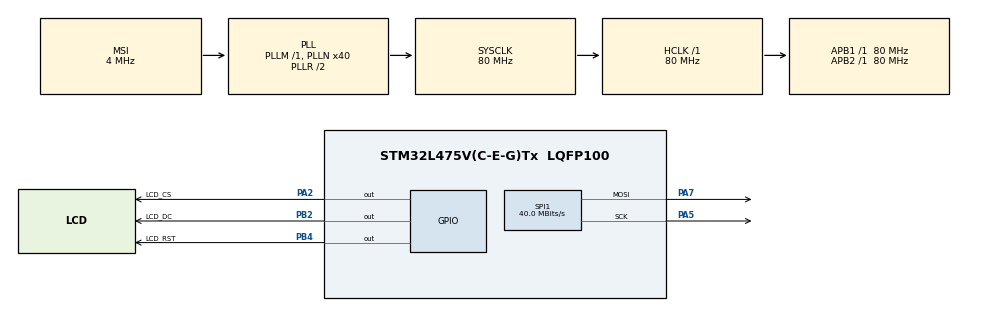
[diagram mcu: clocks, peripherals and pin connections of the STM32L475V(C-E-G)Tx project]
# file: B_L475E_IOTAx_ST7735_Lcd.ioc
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Mcu.Family=STM32L4
Mcu.Name=STM32L475V(C-E-G)Tx
Mcu.Package=LQFP100
NVIC.PriorityGroup=NVIC_PRIORITYGROUP_4
PA13\ (JTMS-SWDIO).Mode=Trace_Asynchronous_SW
PA13\ (JTMS-SWDIO).Signal=SYS_JTMS-SWDIO
PA14\ (JTCK-SWCLK).Mode=Trace_Asynchronous_SW
PA14\ (JTCK-SWCLK).Signal=SYS_JTCK-SWCLK
PA2.GPIO_Label=LCD_CS
PA2.Signal=GPIO_Output
PA5.Mode=TX_Only_Simplex_Unidirect_Master
PA5.Signal=SPI1_SCK
PA7.Mode=TX_Only_Simplex_Unidirect_Master
PA7.Signal=SPI1_MOSI
PB2.GPIO_Label=LCD_DC
PB2.Signal=GPIO_Output
PB3\ (JTDO-TRACESWO).Mode=Trace_Asynchronous_SW
PB3\ (JTDO-TRACESWO).Signal=SYS_JTDO-SWO
PB4\ (NJTRST).GPIO_Label=LCD_RST
PB4\ (NJTRST).Signal=GPIO_Output
ProjectManager.HeapSize=0x200
ProjectManager.StackSize=0x400
ProjectManager.TargetToolchain=STM32CubeIDE
RCC.ADCFreq_Value=48000000
RCC.AHBFreq_Value=80000000
RCC.APB1Freq_Value=80000000
RCC.APB1TimFreq_Value=80000000
RCC.APB2Freq_Value=80000000
RCC.APB2TimFreq_Value=80000000
RCC.CortexFreq_Value=80000000
RCC.HCLKFreq_Value=80000000
RCC.HSE_VALUE=8000000
RCC.HSI_VALUE=16000000
RCC.LSE_VALUE=32768
RCC.MSI_VALUE=4000000
RCC.PLLN=40
RCC.PLLSAI1N=24
RCC.SYSCLKFreq_VALUE=80000000
RCC.SYSCLKSource=RCC_SYSCLKSOURCE_PLLCLK
RCC.USBFreq_Value=48000000
RCC.VCOOutputFreq_Value=160000000
SPI1.BaudRatePrescaler=SPI_BAUDRATEPRESCALER_2
SPI1.CalculateBaudRate=40.0 MBits/s
SPI1.DataSize=SPI_DATASIZE_8BIT
SPI1.Direction=SPI_DIRECTION_2LINES
SPI1.Mode=SPI_MODE_MASTER
SPI1.NSSPMode=SPI_NSS_PULSE_DISABLE
SPI1.VirtualType=VM_MASTER
board=B-L475E-IOT01A1

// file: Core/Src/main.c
/* USER CODE BEGIN Header */
/**
  ******************************************************************************
  * @file           : main.c
  * @brief          : Main program body
  ******************************************************************************
  * @attention
  *
  * <h2><center>&copy; Copyright (c) 2020 STMicroelectronics.
  * All rights reserved.</center></h2>
  *
  * This software component is licensed by ST under BSD 3-Clause license,
  * the "License"; You may not use this file except in compliance with the
  * License. You may obtain a copy of the License at:
  *                        opensource.org/licenses/BSD-3-Clause
  *
  ******************************************************************************
  */
/* USER CODE END Header */

#include "main.h"

/* USER CODE BEGIN Includes */
#include <string.h>
#include <stdio.h>
#include "st7735.h"

/* USER CODE END Includes */

SPI_HandleTypeDef hspi1;

/* USER CODE BEGIN PV */
uint8_t val;
char str[4];

/* USER CODE END PV */

void SystemClock_Config(void);
static void MX_GPIO_Init(void);
static void MX_SPI1_Init(void);

int main(void)
{

  /* MCU Configuration--------------------------------------------------------*/

  /* Reset of all peripherals, Initializes the Flash interface and the Systick. */
  HAL_Init();

  /* Configure the system clock */
  SystemClock_Config();

  /* Initialize all configured peripherals */
  MX_GPIO_Init();
  MX_SPI1_Init();
  /* USER CODE BEGIN 2 */

  /**> Initialize 1.8inch LCD */
  LcdInit();

  /**> Configure Screen and Rotation */
  fillScreen(ST7735_GREY);
  setRotation(1);

  /* USER CODE END 2 */

  /* Infinite loop */
  /* USER CODE BEGIN WHILE */
  while (1)
  {
 		val++;
  	sprintf(str, "%3d", val);
  	drawString(str, 0, 0, ST7735_BLACK, ST7735_GREY, 3);
  	HAL_Delay(250);
  	/* USER CODE END WHILE */

  }
}

void SystemClock_Config(void)
{
  RCC_OscInitTypeDef RCC_OscInitStruct = {0};
  RCC_ClkInitTypeDef RCC_ClkInitStruct = {0};

  /** Initializes the CPU, AHB and APB busses clocks
  */
  RCC_OscInitStruct.OscillatorType = RCC_OSCILLATORTYPE_MSI;
  RCC_OscInitStruct.MSIState = RCC_MSI_ON;
  RCC_OscInitStruct.MSICalibrationValue = 0;
  RCC_OscInitStruct.MSIClockRange = RCC_MSIRANGE_6;
  RCC_OscInitStruct.PLL.PLLState = RCC_PLL_ON;
  RCC_OscInitStruct.PLL.PLLSource = RCC_PLLSOURCE_MSI;
  RCC_OscInitStruct.PLL.PLLM = 1;
  RCC_OscInitStruct.PLL.PLLN = 40;
  RCC_OscInitStruct.PLL.PLLP = RCC_PLLP_DIV7;
  RCC_OscInitStruct.PLL.PLLQ = RCC_PLLQ_DIV2;
  RCC_OscInitStruct.PLL.PLLR = RCC_PLLR_DIV2;
  if (HAL_RCC_OscConfig(&RCC_OscInitStruct) != HAL_OK)
  {
    Error_Handler();
  }
  /** Initializes the CPU, AHB and APB busses clocks
  */
  RCC_ClkInitStruct.ClockType = RCC_CLOCKTYPE_HCLK|RCC_CLOCKTYPE_SYSCLK
                              |RCC_CLOCKTYPE_PCLK1|RCC_CLOCKTYPE_PCLK2;
  RCC_ClkInitStruct.SYSCLKSource = RCC_SYSCLKSOURCE_PLLCLK;
  RCC_ClkInitStruct.AHBCLKDivider = RCC_SYSCLK_DIV1;
  RCC_ClkInitStruct.APB1CLKDivider = RCC_HCLK_DIV1;
  RCC_ClkInitStruct.APB2CLKDivider = RCC_HCLK_DIV1;

  if (HAL_RCC_ClockConfig(&RCC_ClkInitStruct, FLASH_LATENCY_4) != HAL_OK)
  {
    Error_Handler();
  }
  /** Configure the main internal regulator output voltage
  */
  if (HAL_PWREx_ControlVoltageScaling(PWR_REGULATOR_VOLTAGE_SCALE1) != HAL_OK)
  {
    Error_Handler();
  }
}

static void MX_SPI1_Init(void)
{

  /* SPI1 parameter configuration*/
  hspi1.Instance = SPI1;
  hspi1.Init.Mode = SPI_MODE_MASTER;
  hspi1.Init.Direction = SPI_DIRECTION_2LINES;
  hspi1.Init.DataSize = SPI_DATASIZE_8BIT;
  hspi1.Init.CLKPolarity = SPI_POLARITY_LOW;
  hspi1.Init.CLKPhase = SPI_PHASE_1EDGE;
  hspi1.Init.NSS = SPI_NSS_SOFT;
  hspi1.Init.BaudRatePrescaler = SPI_BAUDRATEPRESCALER_2;
  hspi1.Init.FirstBit = SPI_FIRSTBIT_MSB;
  hspi1.Init.TIMode = SPI_TIMODE_DISABLE;
  hspi1.Init.CRCCalculation = SPI_CRCCALCULATION_DISABLE;
  hspi1.Init.CRCPolynomial = 7;
  hspi1.Init.CRCLength = SPI_CRC_LENGTH_DATASIZE;
  hspi1.Init.NSSPMode = SPI_NSS_PULSE_DISABLE;
  if (HAL_SPI_Init(&hspi1) != HAL_OK)
  {
    Error_Handler();
  }

}

static void MX_GPIO_Init(void)
{
  GPIO_InitTypeDef GPIO_InitStruct = {0};

  /* GPIO Ports Clock Enable */
  __HAL_RCC_GPIOA_CLK_ENABLE();
  __HAL_RCC_GPIOB_CLK_ENABLE();

  /*Configure GPIO pin Output Level */
  HAL_GPIO_WritePin(LCD_CS_GPIO_Port, LCD_CS_Pin, GPIO_PIN_RESET);

  /*Configure GPIO pin Output Level */
  HAL_GPIO_WritePin(GPIOB, LCD_DC_Pin|LCD_RST_Pin, GPIO_PIN_RESET);

  /*Configure GPIO pin : LCD_CS_Pin */
  GPIO_InitStruct.Pin = LCD_CS_Pin;
  GPIO_InitStruct.Mode = GPIO_MODE_OUTPUT_PP;
  GPIO_InitStruct.Pull = GPIO_NOPULL;
  GPIO_InitStruct.Speed = GPIO_SPEED_FREQ_LOW;
  HAL_GPIO_Init(LCD_CS_GPIO_Port, &GPIO_InitStruct);

  /*Configure GPIO pins : LCD_DC_Pin LCD_RST_Pin */
  GPIO_InitStruct.Pin = LCD_DC_Pin|LCD_RST_Pin;
  GPIO_InitStruct.Mode = GPIO_MODE_OUTPUT_PP;
  GPIO_InitStruct.Pull = GPIO_NOPULL;
  GPIO_InitStruct.Speed = GPIO_SPEED_FREQ_LOW;
  HAL_GPIO_Init(GPIOB, &GPIO_InitStruct);

}

void Error_Handler(void)
{
}

/************************ (C) COPYRIGHT STMicroelectronics *****END OF FILE****/
